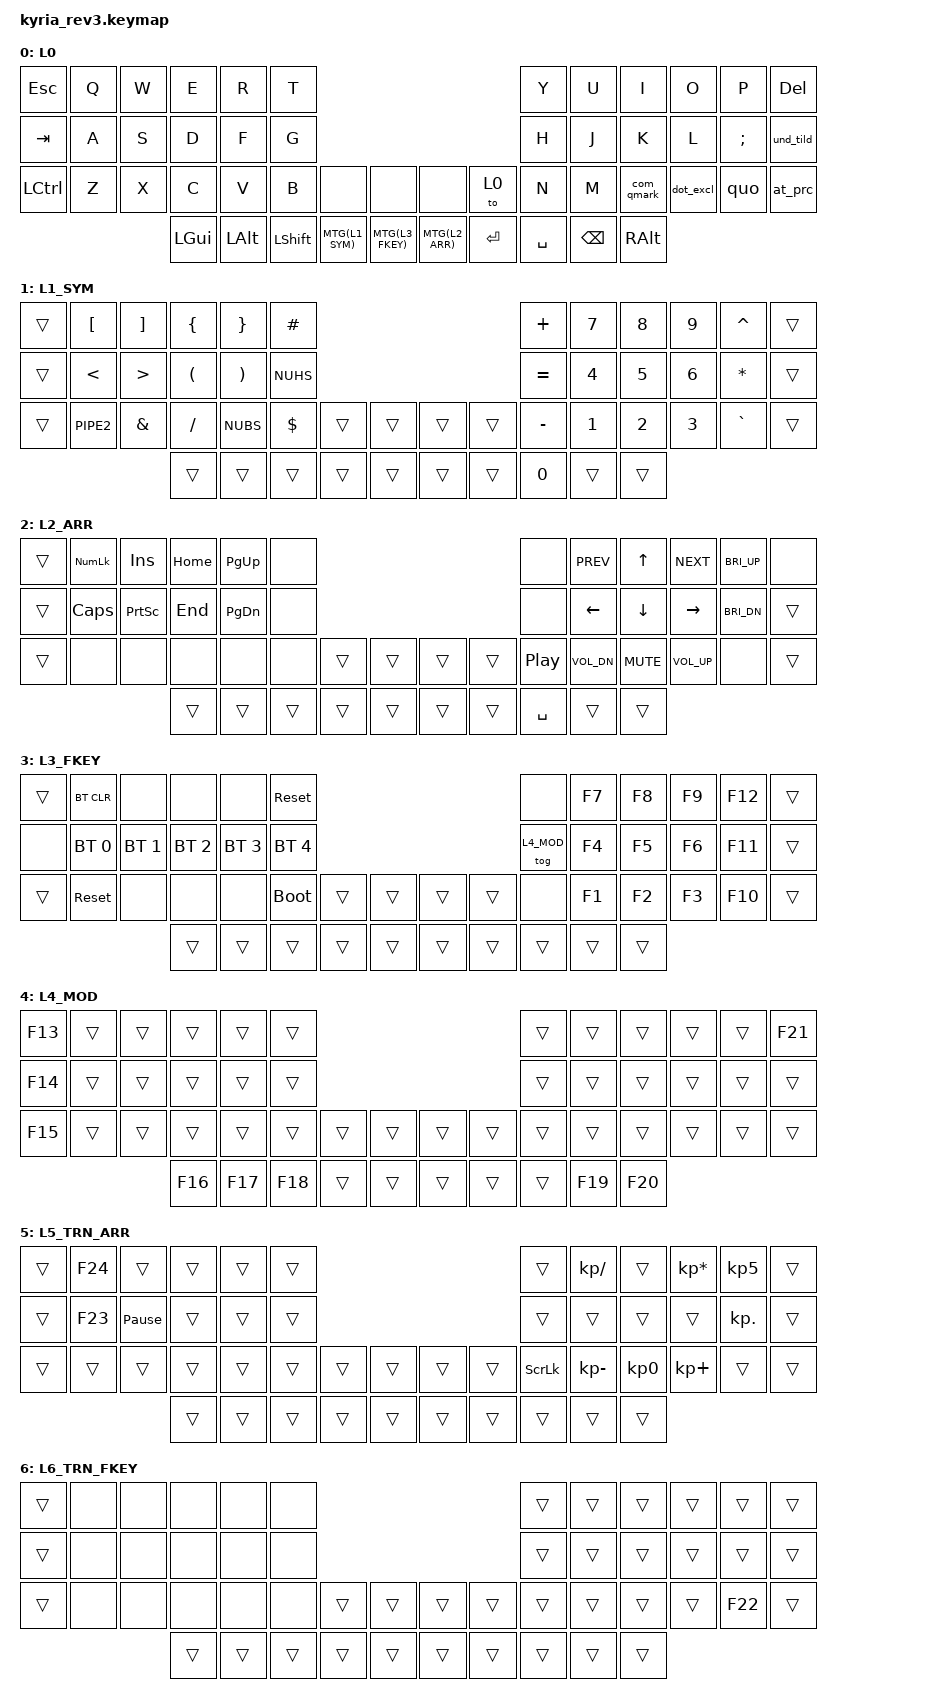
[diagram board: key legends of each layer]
/* Copyright (c) 2023 The ZMK Contributors
 * SPDX-License-Identifier: MIT */

#include <behaviors.dtsi>
#include <dt-bindings/zmk/keys.h>
#include <dt-bindings/zmk/bt.h>

#define L0 0
#define L1_SYM 1
#define L2_ARR 2
#define L3_FKEY 3
#define L4_MOD 4
#define L5_TRN_ARR 5
#define L6_TRN_FKEY 6

#define MTG(layer) &mo_tog layer layer   // Macro to apply momentary-layer-on-hold/toggle-layer-on-tap to a specific layer

#define combo_timeout 30
#define combo_timeout_long 60
#define combo_global_quick_tap 150
#define combo_global_quick_tap_long 300



/ {
    //combos {
    //    compatible = "zmk,combos";
    //    combo_L2 {
    //        timeout-ms = <combo_timeout>;
    //        key-positions = <30 43>;
    //        //layers = <BASE WIN NAV NUM>;
    //        bindings = <&mo L2>;
    //    };
    //    combo_L3 {
    //        timeout-ms = <combo_timeout>;
    //        key-positions = <43 44>;
    //        //layers = <BASE WIN NAV NUM>;
    //        bindings = <&mo L3>;
    //    };
    //};

    behaviors {
        mo_tog: behavior_mo_tog {
            compatible = "zmk,behavior-hold-tap";
            #binding-cells = <2>;
            flavor = "hold-preferred";
            tapping-term-ms = <200>;
            bindings = <&mo>, <&tog>;
        };
        round: round {
            compatible = "zmk,behavior-mod-morph";
            label = "round";
            #binding-cells = <0>;
            bindings = <&kp LPAR>, <&kp RPAR>;
            mods = <(MOD_LSFT|MOD_RSFT)>;
        };
        square: square {
            compatible = "zmk,behavior-mod-morph";
            label = "square";
            #binding-cells = <0>;
            bindings = <&kp LBKT>, <&kp RBKT>;
            mods = <(MOD_LSFT|MOD_RSFT)>;
        };
        curly: curly {
            compatible = "zmk,behavior-mod-morph";
            label = "curly";
            #binding-cells = <0>;
            bindings = <&kp LBRC>, <&kp RBRC>;
            mods = <(MOD_LSFT|MOD_RSFT)>;
        };
        angled: angled {
            compatible = "zmk,behavior-mod-morph";
            label = "angled";
            #binding-cells = <0>;
            bindings = <&kp LT>, <&kp GT>;
            mods = <(MOD_LSFT|MOD_RSFT)>;
        };
        bslash_ex: bslash_ex {
            compatible = "zmk,behavior-mod-morph";
            label = "bslash_ex";
            #binding-cells = <0>;
            bindings = <&kp BSLH>, <&kp EXCLAMATION>;
            mods = <(MOD_LSFT|MOD_RSFT)>;
        };
        slash: slash {
            compatible = "zmk,behavior-mod-morph";
            label = "slash";
            #binding-cells = <0>;
            bindings = <&kp FSLH>, <&kp BSLH>;
            mods = <(MOD_LSFT|MOD_RSFT)>;
        };

        // Double symbols
        com_qmark: com_qmark { // , !
            compatible = "zmk,behavior-mod-morph";
            label = "com_qmark";
            #binding-cells = <0>;
            bindings = <&kp COMMA>, <&kp QMARK>;
            mods = <(MOD_LSFT|MOD_RSFT)>;
        };

        und_tild: und_tild { // , !
            compatible = "zmk,behavior-mod-morph";
            label = "und_tild";
            #binding-cells = <0>;
            bindings = <&kp UNDER>, <&kp TILDE2>;
            mods = <(MOD_LSFT|MOD_RSFT)>;
        };

        dot_excl: dot_excl { // . !
            compatible = "zmk,behavior-mod-morph";
            label = "dot_excl";
            #binding-cells = <0>;
            bindings = <&kp DOT>, <&kp EXCLAMATION>;
            mods = <(MOD_LSFT|MOD_RSFT)>;
        };

        qmark: qmark { // ? !
            compatible = "zmk,behavior-mod-morph";
            label = "qmark";
            #binding-cells = <0>;
            bindings = <&kp QMARK>, <&kp EXCLAMATION>;
            mods = <(MOD_LSFT|MOD_RSFT)>;
        };
        money: money { // £ $
            compatible = "zmk,behavior-mod-morph";
            label = "money";
            #binding-cells = <0>;
            bindings = <&kp DOLLAR>, <&kp POUND>;
            mods = <(MOD_LSFT|MOD_RSFT)>;
        };
        bool: bool { // & |
            compatible = "zmk,behavior-mod-morph";
            label = "bool";
            #binding-cells = <0>;
            bindings = <&kp AMPERSAND>, <&kp PIPE>;
            mods = <(MOD_LSFT|MOD_RSFT)>;
        };
        hash: hash { // # ~
            compatible = "zmk,behavior-mod-morph";
            label = "hash";
            #binding-cells = <0>;
            bindings = <&kp HASH>, <&kp TILDE>;
            mods = <(MOD_LSFT|MOD_RSFT)>;
        };
        quo: quo {
            compatible = "zmk,behavior-mod-morph";
            label = "quotes";
            #binding-cells = <0>;
            bindings = <&kp SQT>, <&kp AT_SIGN>;
            mods = <(MOD_LSFT|MOD_RSFT)>;
        };
        at_prc: at_prc { // @ %
            compatible = "zmk,behavior-mod-morph";
            label = "at_prc";
            #binding-cells = <0>;
            bindings = <&kp PERCENT>, <&kp DQT>;
            mods = <(MOD_LSFT|MOD_RSFT)>;
        };
    };

    macros {
        hard_dqt: hard_dqt {
            compatible = "zmk,behavior-macro";
            #binding-cells = <0>;
            bindings
                = <&macro_press   &kp LALT>
                , <&macro_tap     &kp KP_N3 &kp KP_N4>
                , <&macro_release &kp LALT>
                ;
            label = "HARD_DQT";
        };
        hard_money: hard_money {
            compatible = "zmk,behavior-macro";
            #binding-cells = <0>;
            bindings
                = <&macro_press   &kp LALT>
                , <&macro_tap     &kp KP_N0 &kp KP_N1 &kp KP_N6 &kp KP_N3>
                , <&macro_release &kp LALT>
                ;
            label = "HARD_MONEY";
        };
    };

    // The training layers switch on by themselves when L4_MOD is active together with L2_ARR / L3_FKEY
    conditional_layers {
        compatible = "zmk,conditional-layers";
        training_arrows {
            if-layers = <L2_ARR L4_MOD>;
            then-layer = <L5_TRN_ARR>;
        };
        training_fkeys {
            if-layers = <L3_FKEY L4_MOD>;
            then-layer = <L6_TRN_FKEY>;
        };
    };

    keymap {
        compatible = "zmk,keymap";


// Move TILDE to underscore and then POUND and DOLLAR around hash, GRAVE instead of FLSH near numbers
// home, end, pg up, pg down maybe do vertically
// check where pg up and down and home, end keys actually apply exactly
// do i not need the L1_SYM actually? can I put another level key there from right side and make space there for shift or other key to have a duplicate
// if needed for keyboard shortcuts

L0 {
bindings = <
//╭─0─────────┬─1─────────┬─2─────────┬─3─────────┬─4─────────┬─5─────────╮            LETTERS + BASE CTRL KEYS             ╭─6─────────┬─7─────────┬─8─────────┬─9─────────┬─10────────┬─11────────╮
  &kp   ESC   &kp   Q     &kp   W     &kp   E     &kp   R     &kp   T                                                       &kp    Y    &kp    U    &kp    I    &kp    O    &kp    P    &kp  DEL
//├─12────────┼─13────────┼─14────────┼─15────────┼─16────────┼─17────────┤                                                 ├─18────────┼─19────────┼─20────────┼─21────────┼─22─ ; : ──┼─23─ _ ~  ─┤
  &kp   TAB   &kp   A     &kp   S     &kp   D     &kp   F     &kp   G                                                       &kp    H    &kp    J    &kp    K    &kp    L    &kp   SEMI  &und_tild
//├─24────────┼─25────────┼─26────────┼─27────────┼─28────────┼─29────────┼─30────────┬─31────────╮ ╭─32────────┬─33────────┼─34────────┼─35────────┼─36─ , ? ──┼─37─ . ! ──┼─38─ ' " ──┼─39─ % @ ──┤
  &kp  LCTRL  &kp   Z     &kp   X     &kp   C     &kp   V     &kp   B     &none       &none         &none       &to  L0     &kp    N    &kp    M    &com_qmark  &dot_excl   &quo        &at_prc
//╰───────────┴───────────┴───────────┼─40────────┼─41───────┬┼┬42────────┼─43────────┬─44────────┤ ├─45────────┬─46────────┼─47───────┬┼┬48────────┼─49────────┼───────────┴───────────┴───────────╯
                                      &kp  LGUI   &kp  LALT   &kp  LSHFT  MTG(L1_SYM) MTG(L3_FKEY)  MTG(L2_ARR) &kp   RET   &kp SPACE   &kp  BSPC   &kp RALT
//                                    ╰───────────┴──────────┴┴┴──────────┴───────────┴───────────╯ ╰───────────┴───────────┴──────────┴┴┴──────────┴───────────╯
>;
sensor-bindings = <&inc_dec_kp C_VOL_UP C_VOL_DN &inc_dec_kp C_VOL_UP C_VOL_DN>;
};

L1_SYM {
bindings = <
//╭───────────┬───  [  ───┬───  ]  ───┬───  {  ───┬───  }  ───┬──── £ ────╮            SYMBOLS + NUMERIC + CALC             ╭──── + ────┬───────────┬───────────┬───────────┬──── ^ ────┬───────────╮
  &trans      &kp  LBKT   &kp  RBKT   &kp  LBRC   &kp  RBRC   &kp POUND                                                     &kp PLUS    &kp   N7   &kp   N8     &kp   N9    &kp  CARET  &trans
//├───────────┼───  <  ───┼───  >  ───┼───  (  ───┼───  )  ───┼──── # ────┤                                                 ├───  =  ───┼───────────┼───────────┼───────────┼──── * ────┼───────────┤
  &trans      &kp  LT     &kp  GT     &kp  LPAR   &kp  RPAR   &kp NUHS                                                      &kp EQUAL   &kp   N4   &kp   N5     &kp   N6    &kp  STAR   &trans
//├───────────┼──── | ────┼──── & ────┼───  /  ───┼───  \  ───┼───  $  ───┼───────────┬───────────╮ ╭───────────┬───────────┼───  -  ───┼───────────┼───────────┼───────────┼──── ` ────┼───────────┤
  &trans      &kp PIPE2   &kp AMPS    &kp  FSLH   &kp  NUBS   &kp DOLLAR  &trans      &trans        &trans      &trans      &kp MINUS   &kp   N1    &kp  N2     &kp   N3    &kp  GRAVE  &trans
//╰───────────┴───────────┴───────────┼───────────┼──────────┬┼┬──────────┼───────────┬───────────┤ ├───────────┬───────────┼──────────┬┼┬──────────┼───────────┼───────────┴───────────┴───────────╯
                                      &trans      &trans      &trans      &trans      &trans        &trans      &trans      &kp  N0     &trans      &trans
//                                    ╰───────────┴──────────┴┴┴──────────┴───────────┴───────────╯ ╰───────────┴───────────┴──────────┴┴┴──────────┴───────────╯
>;
sensor-bindings = <&inc_dec_kp PG_UP PG_DN &inc_dec_kp PG_UP PG_DN>;
};

L2_ARR {
bindings = <
//╭───────────┬───────────┬───────────┬───────────┬───────────┬───────────╮               ARROWS + MEDIA                    ╭───────────┬─── << ────┬───────────┬─── >> ────┬───────────┬───────────╮
  &trans      &kp KP_NUM  &kp INSERT  &kp HOME    &kp PG_UP   &none                                                         &none       &kp C_PREV  &kp   UP    &kp C_NEXT  &kp C_BRI_UP &none
//├───────────┼───────────┼───────────┼───────────┼───────────┼───────────┤                                                 ├───────────┼───────────┼───────────┼───────────┼───────────┼───────────┤
  &trans      &kp CAPS    &kp PSCRN   &kp END     &kp PG_DN   &none                                                         &none       &kp  LEFT   &kp  DOWN   &kp  RIGHT  &kp C_BRI_DN &trans
//├───────────┼───────────┼───────────┼───────────┼───────────┼───────────┼───────────┬───────────╮ ╭───────────┬───────────┼──── ⏯ ────┼── VOL - ──┼─── MUTE ──┼── VOL + ──┼───────────┼───────────┤
  &trans      &none       &none       &none       &none       &none       &trans      &trans        &trans      &trans      &kp C_PP   &kp C_VOL_DN &kp C_MUTE  &kp C_VOL_UP &none      &trans
//╰───────────┴───────────┴───────────┼───────────┼──────────┬┼┬──────────┼───────────┬───────────┤ ├───────────┬───────────┼──────────┬┼┬──────────┼───────────┼───────────┴───────────┴───────────╯
                                      &trans      &trans      &trans      &trans      &trans        &trans      &trans      &kp SPACE   &trans      &trans
//                                    ╰───────────┴──────────┴┴┴──────────┴───────────┴───────────╯ ╰───────────┴───────────┴──────────┴┴┴──────────┴───────────╯
>;
sensor-bindings = <&inc_dec_kp C_VOL_UP C_VOL_DN &inc_dec_kp C_BRI_INC C_BRI_DEC>;
};

L3_FKEY {
bindings = <
//╭───────────┬───────────┬───────────┬───────────┬───────────┬───────────╮               F Keys                            ╭───────────┬───────────┬───────────┬───────────┬───────────┬───────────╮
  &trans      &bt BT_CLR  &none       &none       &none       &sys_reset                                                    &none       &kp   F7    &kp   F8    &kp   F9    &kp   F12   &trans
//├───────────┼───────────┼───────────┼───────────┼───────────┼───────────┤                                                 ├───────────┼───────────┼───────────┼───────────┼───────────┼───────────┤
  &none       &bt BT_SEL 0 &bt BT_SEL 1 &bt BT_SEL 2 &bt BT_SEL 3 &bt BT_SEL 4                                              &tog L4_MOD &kp   F4    &kp   F5    &kp   F6    &kp   F11   &trans
//├───────────┼───────────┼───────────┼───────────┼───────────┼───────────┼───────────┬───────────╮ ╭───────────┬───────────┼───────────┼───────────┼───────────┼───────────┼───────────┼───────────┤
  &trans      &sys_reset  &none       &none       &none       &bootloader &trans      &trans        &trans      &trans      &none       &kp   F1    &kp   F2    &kp   F3    &kp   F10   &trans
//╰───────────┴───────────┴───────────┼───────────┼──────────┬┼┬──────────┼───────────┬───────────┤ ├───────────┬───────────┼──────────┬┼┬──────────┼───────────┼───────────┴───────────┴───────────╯
                                      &trans      &trans      &trans      &trans      &trans        &trans      &trans      &trans      &trans      &trans
//                                    ╰───────────┴──────────┴┴┴──────────┴───────────┴───────────╯ ╰───────────┴───────────┴──────────┴┴┴──────────┴───────────╯
>;
sensor-bindings = <&inc_dec_kp LEFT RIGHT &inc_dec_kp LEFT RIGHT>;
};

L4_MOD {
bindings = <
// F13 = 'ESC'
// F14 = 'TAB'
// F15 = 'LCTRL'
// F16 = 'LGUI'
// F17 = 'LALT'
// F18 = 'LSHFT'
// F19 = 'BSPC'
// F20 = 'RALT'
// F21 = 'DEL'
//╭─0─────────┬─1─────────┬─2─────────┬─3─────────┬─4─────────┬─5─────────╮             SPECIAL TRAINING LAYER              ╭─6─────────┬─7─────────┬─8─────────┬─9─────────┬─10────────┬─11────────╮
  &kp   F13   &trans      &trans      &trans      &trans      &trans                                                        &trans      &trans      &trans      &trans      &trans      &kp F21
//├─12────────┼─13────────┼─14────────┼─15────────┼─16────────┼─17────────┤                                                 ├─18────────┼─19────────┼─20────────┼─21────────┼─22─ ; : ──┼─23─ _ ~  ─┤
  &kp   F14   &trans      &trans      &trans      &trans      &trans                                                        &trans      &trans      &trans      &trans      &trans      &trans
//├─24────────┼─25────────┼─26────────┼─27────────┼─28────────┼─29────────┼─30────────┬─31────────╮ ╭─32────────┬─33────────┼─34────────┼─35────────┼─36─ , ? ──┼─37─ . ! ──┼─38─ ' " ──┼─39─ % @ ──┤
  &kp   F15   &trans      &trans      &trans      &trans      &trans      &trans      &trans        &trans      &trans      &trans      &trans      &trans      &trans      &trans      &trans
//╰───────────┴───────────┴───────────┼─40────────┼─41───────┬┼┬42────────┼─43────────┬─44────────┤ ├─45────────┬─46────────┼─47───────┬┼┬48────────┼─49────────┼───────────┴───────────┴───────────╯
                                      &kp F16     &kp F17    &kp F18      &trans      &trans        &trans      &trans      &trans      &kp F19     &kp F20
//                                    ╰───────────┴──────────┴┴┴──────────┴───────────┴───────────╯ ╰───────────┴───────────┴──────────┴┴┴──────────┴───────────╯
>;
sensor-bindings = <&inc_dec_kp C_VOL_UP C_VOL_DN &inc_dec_kp C_VOL_UP C_VOL_DN>;
};

L5_TRN_ARR {
bindings = <
// Active when L2_ARR + L4_MOD are both on
// F23         = 'CAPS'        SLCK        = 'C_PP'        KP_PLUS  = 'C_VOL_UP'    KP_N5  = 'C_BRI_UP'
// F24         = 'KP_NUM'      KP_DIVIDE   = 'C_PREV'      KP_MINUS = 'C_VOL_DN'    KP_DOT = 'C_BRI_DN'
// PAUSE_BREAK = 'PSCRN'       KP_MULTIPLY = 'C_NEXT'      KP_N0    = 'C_MUTE'
//╭───────────┬── NUMLK ──┬── INSERT ─┬── HOME ───┬── PG_UP ──┬───────────╮           TRAINING: ARROWS + MEDIA              ╭───────────┬─── << ────┬───────────┬─── >> ────┬── BRI + ──┬───────────╮
  &trans      &kp F24     &trans      &trans      &trans      &trans                                                        &trans      &kp KP_DIVIDE &trans    &kp KP_MULTIPLY &kp KP_N5 &trans
//├───────────┼── CAPS ───┼── PSCRN ──┼── END ────┼── PG_DN ──┼───────────┤                                                 ├───────────┼───────────┼───────────┼───────────┼── BRI - ──┼───────────┤
  &trans      &kp F23     &kp PAUSE_BREAK &trans  &trans      &trans                                                        &trans      &trans      &trans      &trans      &kp KP_DOT  &trans
//├───────────┼───────────┼───────────┼───────────┼───────────┼───────────┼───────────┬───────────╮ ╭───────────┬───────────┼──── ⏯ ────┼── VOL - ──┼─── MUTE ──┼── VOL + ──┼───────────┼───────────┤
  &trans      &trans      &trans      &trans      &trans      &trans      &trans      &trans        &trans      &trans      &kp SLCK    &kp KP_MINUS &kp KP_N0  &kp KP_PLUS &trans      &trans
//╰───────────┴───────────┴───────────┼───────────┼──────────┬┼┬──────────┼───────────┬───────────┤ ├───────────┬───────────┼──────────┬┼┬──────────┼───────────┼───────────┴───────────┴───────────╯
                                      &trans      &trans      &trans      &trans      &trans        &trans      &trans      &trans      &trans      &trans
//                                    ╰───────────┴──────────┴┴┴──────────┴───────────┴───────────╯ ╰───────────┴───────────┴──────────┴┴┴──────────┴───────────╯
>;
sensor-bindings = <&inc_dec_kp C_VOL_UP C_VOL_DN &inc_dec_kp C_VOL_UP C_VOL_DN>;
};

L6_TRN_FKEY {
bindings = <
// Active when L3_FKEY + L4_MOD are both on
// F22 = 'F10'
// bluetooth / reset / bootloader are switched off here so a slip cannot kill the practice session.
// Position 18 stays &trans so `&tog L4_MOD` on L3_FKEY is still reachable to leave training.
//╭───────────┬───────────┬───────────┬───────────┬───────────┬───────────╮             TRAINING: F Keys                    ╭───────────┬─── F7 ────┬─── F8 ────┬─── F9 ────┬─── F12 ───┬───────────╮
  &trans      &none       &none       &none       &none       &none                                                         &trans      &trans      &trans      &trans      &trans      &trans
//├───────────┼───────────┼───────────┼───────────┼───────────┼───────────┤                                                 ├─ tog L4 ──┼─── F4 ────┼─── F5 ────┼─── F6 ────┼─── F11 ───┼───────────┤
  &trans      &none       &none       &none       &none       &none                                                         &trans      &trans      &trans      &trans      &trans      &trans
//├───────────┼───────────┼───────────┼───────────┼───────────┼───────────┼───────────┬───────────╮ ╭───────────┬───────────┼───────────┼─── F1 ────┼─── F2 ────┼─── F3 ────┼─── F10 ───┼───────────┤
  &trans      &none       &none       &none       &none       &none       &trans      &trans        &trans      &trans      &trans      &trans      &trans      &trans      &kp F22     &trans
//╰───────────┴───────────┴───────────┼───────────┼──────────┬┼┬──────────┼───────────┬───────────┤ ├───────────┬───────────┼──────────┬┼┬──────────┼───────────┼───────────┴───────────┴───────────╯
                                      &trans      &trans      &trans      &trans      &trans        &trans      &trans      &trans      &trans      &trans
//                                    ╰───────────┴──────────┴┴┴──────────┴───────────┴───────────╯ ╰───────────┴───────────┴──────────┴┴┴──────────┴───────────╯
>;
sensor-bindings = <&inc_dec_kp LEFT RIGHT &inc_dec_kp LEFT RIGHT>;
};

    };
};
